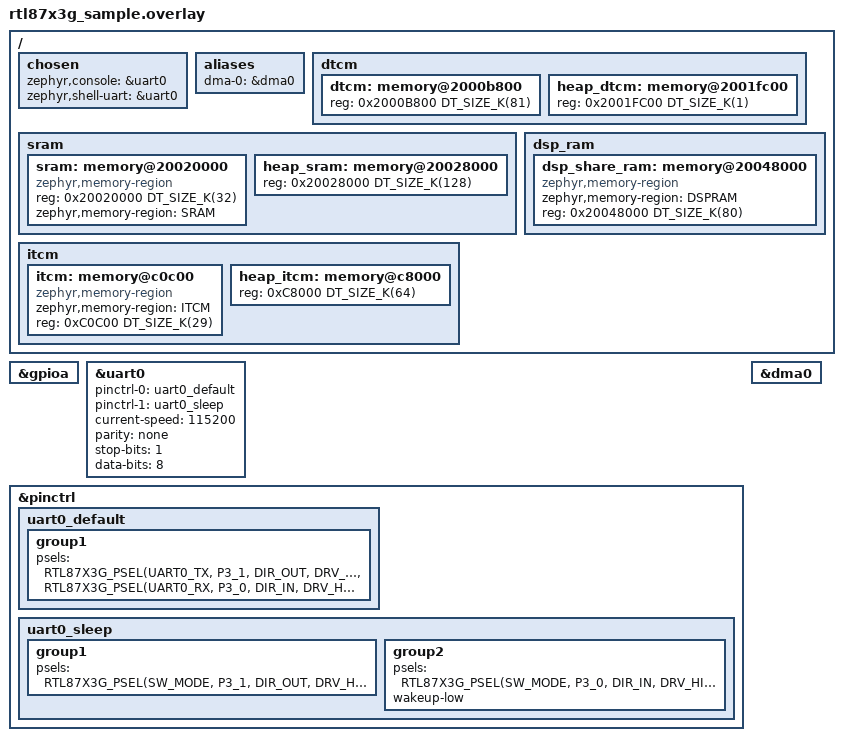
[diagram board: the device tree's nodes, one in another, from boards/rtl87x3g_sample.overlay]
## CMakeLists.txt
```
#
# Copyright (c) 2026, Realtek Semiconductor Corporation
#
# SPDX-License-Identifier: LicenseRef-Realtek-5-Clause
#

message(STATUS "CMAKELIST FOLDER: ${CMAKE_CURRENT_SOURCE_DIR}")

cmake_minimum_required(VERSION 3.20.0)

#===========version generation===========
include(${CMAKE_CURRENT_SOURCE_DIR}/../../cmake/version_generate.cmake)
generate_version()
#===========version generation===========
#===========post build===========
# post build should be called before find_package
include(${CMAKE_CURRENT_SOURCE_DIR}/../../cmake/post_build.cmake)
rtk_post_build()
#===========post build===========

find_package(Zephyr REQUIRED HINTS $ENV{ZEPHYR_BASE})
project(ble_scatternet)

FILE(GLOB app_sources src/*.c)
target_sources(app PRIVATE
  ${app_sources}
  )

set(sources
   ${ZEPHYR_REALTEK_APP_MODULE_DIR}/subsys/bluetooth/gatt_profile/src/client/ancs_client.c
   ${ZEPHYR_REALTEK_APP_MODULE_DIR}/subsys/bluetooth/gatt_profile/src/client/bas_client.c
   ${ZEPHYR_REALTEK_APP_MODULE_DIR}/subsys/bluetooth/gatt_profile/src/client/simple_ble_client.c
   ${ZEPHYR_REALTEK_APP_MODULE_DIR}/subsys/bluetooth/gatt_profile/src/client/gaps_client.c
   ${ZEPHYR_REALTEK_APP_MODULE_DIR}/subsys/bluetooth/gatt_profile/src/server/bas.c
   ${ZEPHYR_REALTEK_APP_MODULE_DIR}/subsys/bluetooth/gatt_profile/src/server/dis.c
   ${ZEPHYR_REALTEK_APP_MODULE_DIR}/subsys/bluetooth/gatt_profile/src/server/simple_ble_service.c
   )

set(headers
    #header files from app
	src/
    #header files from libs
    ${ZEPHYR_REALTEK_APP_MODULE_DIR}/subsys/bluetooth/gatt_profile/inc/bt_gatt_client
    ${ZEPHYR_REALTEK_APP_MODULE_DIR}/subsys/bluetooth/gatt_profile/inc/bt_gatt_svc
    ${ZEPHYR_REALTEK_APP_MODULE_DIR}/subsys/bluetooth/gatt_profile/inc/client
    ${ZEPHYR_REALTEK_APP_MODULE_DIR}/subsys/bluetooth/gatt_profile/inc/server
    )

foreach(header ${headers})
    if(EXISTS ${header})
        zephyr_include_directories(${header})
    else()
        message(FATAL_ERROR "header file directory does not exist: ${header}. Current cmakelist: ${CMAKE_CURRENT_SOURCE_DIR}")
    endif()
endforeach()

foreach(src ${sources})
    if(EXISTS ${src})
        target_sources(app PRIVATE ${src})
    else()
        message(FATAL_ERROR "source file does not exist: ${src}. Current cmakelist: ${CMAKE_CURRENT_SOURCE_DIR}")
    endif()
endforeach()

target_precompile_headers(app PUBLIC
	          ${CMAKE_CURRENT_SOURCE_DIR}/src/app_scatternet_flags.h
			  )

target_include_directories(app PRIVATE src)
```

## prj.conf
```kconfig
# nothing here
CONFIG_REALTEK_SUBSYS_BLE_MGR=y

# Network shell
CONFIG_SERIAL=y
CONFIG_UART_CONSOLE=y
CONFIG_UART_INTERRUPT_DRIVEN=y
CONFIG_UART_ASYNC_API=y
CONFIG_SHELL=y
CONFIG_SHELL_BACKEND_SERIAL=y
CONFIG_LOG_RTK=n
CONFIG_PRINTK=y
CONFIG_HEAP_MEM_POOL_SIZE=1024
CONFIG_CONSOLE=y
#CONFIG_STDOUT_CONSOLE=y

#CONFIG_UART_SHELL_ON_DEV_NAME="UART_2"
#CONFIG_SHELL_PROMPT_UART="uart:~$ "
```

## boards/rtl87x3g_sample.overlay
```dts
/*
 * Copyright(c) 2024, Realtek Semiconductor Corporation.
 *
 * SPDX-License-Identifier: Apache-2.0
 */

#include <zephyr/dt-bindings/gpio/realtek-rtl87x3g-gpio.h>
#include <dt-bindings/pinctrl/rtl87x3g-pinctrl.h>
#include <dt-bindings/input/input-event-codes.h>

&gpioa {
	status = "okay";
};

/ {
    chosen {
        zephyr,console = &uart0;
        zephyr,shell-uart = &uart0;
    };
};

/**
#define GDMA_Handshake_UART0_TX                                     (0)
#define GDMA_Handshake_UART0_RX                                     (1)
#define GDMA_Handshake_UART2_TX                                     (2)
#define GDMA_Handshake_UART2_RX                                     (3)
#define GDMA_Handshake_UART3_TX                                     (48)
#define GDMA_Handshake_UART3_RX                                     (49)
#define GDMA_Handshake_UART4_TX                                     (50)
#define GDMA_Handshake_UART4_RX                                     (51)
#define GDMA_Handshake_UART5_TX                                     (52)
#define GDMA_Handshake_UART5_RX                                     (53)
*/

&uart0 {
	pinctrl-0 = <&uart0_default>;
	pinctrl-1 = <&uart0_sleep>;
	pinctrl-names = "default", "sleep";
	status = "okay";
	current-speed = <115200>;
	parity = "none";
	stop-bits = "1";
	data-bits = <8>;
	//dmas = <&dma0 2 3 0xa>, <&dma0 3 2 0x10021>;
	//dma-names = "rx", "tx";
};

&pinctrl
{
	uart0_default:uart0_default {
		group1 {
			psels = <RTL87X3G_PSEL(UART0_TX, P3_1, DIR_OUT, DRV_HIGH, PULL_UP)>,
			<RTL87X3G_PSEL(UART0_RX, P3_0, DIR_IN, DRV_HIGH, PULL_UP)>;
		};
	};

	uart0_sleep:uart0_sleep {
		group1 {
			psels = <RTL87X3G_PSEL(SW_MODE, P3_1, DIR_OUT, DRV_HIGH, PULL_UP)>;
		};
		group2 {
			psels = <RTL87X3G_PSEL(SW_MODE, P3_0, DIR_IN, DRV_HIGH, PULL_UP)>;
			wakeup-low;
		};
	};
};

&dma0 {
	status = "okay";
};

&gpioa {
	status = "okay";
};

/*delete-node only support nodes with lable */
/delete-node/ &dtcm;
/delete-node/ &heap_dtcm;
/delete-node/ &sram;
/delete-node/ &heap_sram;
/delete-node/ &itcm;
/delete-node/ &heap_itcm;
/delete-node/ &dsp_share_ram;

/ {
	aliases {
		dma-0 = &dma0;
    };

	/* DTCM addr: 0x20000000~0x20020000, total size: 128KByte.
	 * The front 46Kbyte was taken by RTK internal.
	 * If users wants to increase global variables and zephyr static heap,
	 * please follow the steps:
	 * 1. increase dtcm size value "reg = <0x2000B800 DT_SIZE_K(NEW_SIZE)>"
	 * 2. modify heap_dtcm addr label "heap_dtcm: memory@NEW_ADDR"
	 * 3. modify heap_dtcm reg addr "reg = <NEW_ADDR DT_SIZE_K(NEW_SIZE)>"
	 * 4. decrease heap_dtcm size value "reg = <NEW_ADDR DT_SIZE_K(NEW_SIZE)>"
	 * Warning:
	 * 1. the dtcm address should NOT modified!
	 * 2. the dtcm plus heap_dtcm size should NOT exceed 82KByte!
	 */
	dtcm {
		dtcm: memory@2000b800 {
			device_type = "dtcm region";
			reg = <0x2000B800 DT_SIZE_K(81)>;
		};
		heap_dtcm: memory@2001fc00 {
			device_type = "heap dtcm region";
			reg = <0x2001FC00 DT_SIZE_K(1)>;
		};
	};
	/* sram addr: 0x20020000~0x20048000, total size: 160KByte.
	 * call zephyr_code_relocate(FILES xxx.x LOCATION SRAM) at cmakelist could relocate variables on sram.
	 * for more information, please refer to https://docs.zephyrproject.org/latest/kernel/code-relocation.html
	 * If users wants to increase sram size, please follow the steps:
	 * 1. increase sram size value "reg = <0x20020000 DT_SIZE_K(NEW_SIZE)>"
	 * 2. modify heap_sram addr label "heap_sram: memory@NEW_ADDR"
	 * 3. modify heap_sram reg addr "reg = <NEW_ADDR DT_SIZE_K(NEW_SIZE)>"
	 * 4. decrease heap_sram size value "reg = <NEW_ADDR DT_SIZE_K(NEW_SIZE)>"
	 * Warning:
	 * 1. the sram address should NOT modified!
	 * 2. the sram plus heap_sram size should NOT exceed 160KByte!
	 */
	sram {
		sram: memory@20020000 {
			device_type = "sram region";
			compatible = "zephyr,memory-region", "mmio-sram";
			reg = <0x20020000 DT_SIZE_K(32)>;
			zephyr,memory-region = "SRAM";
		};
		heap_sram: memory@20028000 {
			device_type = "heap sram region";
			reg = <0x20028000 DT_SIZE_K(128)>;
		};
	};

	itcm {
		itcm: memory@c0c00 {
			device_type = "itcm region";
			compatible = "zephyr,memory-region", "arm,itcm";
			zephyr,memory-region = "ITCM";
			reg = <0xC0C00 DT_SIZE_K(29)>;
		};
		heap_itcm: memory@c8000 {
			device_type = "heap itcm region";
			reg = <0xC8000 DT_SIZE_K(64)>;
		};
	};

	dsp_ram {
		dsp_share_ram: memory@20048000 {
			compatible = "zephyr,memory-region";
			device_type = "dsp_share_ram region";
			zephyr,memory-region = "DSPRAM";
			reg = <0x20048000 DT_SIZE_K(80)>;
		};
	};
};
```

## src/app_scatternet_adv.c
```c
/*
 * Copyright (c) 2026, Realtek Semiconductor Corporation
 *
 * SPDX-License-Identifier: LicenseRef-Realtek-5-Clause
 */

/*============================================================================*
 *                              Header Files
 *============================================================================*/
#include "ftl.h"
#include "trace.h"
#include "stdint.h"
#include "string.h"
#include "app_shell_cmd.h"
#include "ble_ext_adv.h"
#include "app_scatternet_adv.h"
#include "simple_ble_service.h"

/** @defgroup SCATTERNET_APP Scatternet Application
  * @brief Scatternet Application
  * @{
  */
/*============================================================================*
 *                              Constants
 *============================================================================*/

#define HI_WORD(x)  ((uint8_t)((x & 0xFF00) >> 8))
#define LO_WORD(x)  ((uint8_t)(x))

#define APP_STATIC_RANDOM_ADDR_OFFSET 0xC00

/*============================================================================*
 *                              Variables
 *============================================================================*/
uint8_t adv_handle = 0xFF;
static T_BLE_EXT_ADV_MGR_STATE adv_state = BLE_EXT_ADV_MGR_ADV_DISABLED;

/**
 * @brief scan response data struct
 *
 */
uint8_t scan_rsp_data[] =
{
    0x03,/* length */
    GAP_ADTYPE_APPEARANCE,/* type="Appearance" */
    LO_WORD(GAP_GATT_APPEARANCE_UNKNOWN),
    HI_WORD(GAP_GATT_APPEARANCE_UNKNOWN),
};

/**
 * @brief advertising data struct
 *
 */
uint8_t adv_data[] =
{
    /* Flags */
    0x02,/* length */
    GAP_ADTYPE_FLAGS,/* type="Flags" */
    GAP_ADTYPE_FLAGS_LIMITED | GAP_ADTYPE_FLAGS_BREDR_NOT_SUPPORTED,

    /* Service */
    0x03,/* length */
    GAP_ADTYPE_16BIT_COMPLETE,/*type="16 bit uuid"*/
    LO_WORD(GATT_UUID_SIMPLE_PROFILE),
    HI_WORD(GATT_UUID_SIMPLE_PROFILE),

    /* Local name */
    0x0F,/* length */
    GAP_ADTYPE_LOCAL_NAME_COMPLETE,/*type="name"*/
    'B', 'L', 'E', '_', 'S', 'C', 'A', 'T', 'T', 'E', 'R', 'N', 'E', 'T',
};

/**
 * @brief static random address struct which is storged in ftl
 *
 */
typedef struct
{
    uint8_t is_exist;
    uint8_t reserved;
    uint8_t bd_addr[GAP_BD_ADDR_LEN];
} T_APP_STATIC_RANDOM_ADDR;

/*============================================================================*
 *                              Functions
 *============================================================================*/

/**
 * @brief app_adv_callback
 *
 * @param cb_type
 * @ref BLE_EXT_ADV_STATE_CHANGE this message will be send to APP when advertising state changed
 * @ref BLE_EXT_ADV_SET_CONN_INFO this message will be send to APP when connection state changed
 *
 * @param p_cb_data
 */
void app_adv_callback(uint8_t cb_type, void *p_cb_data)
{
    T_BLE_EXT_ADV_CB_DATA cb_data;
    memcpy(&cb_data, p_cb_data, sizeof(T_BLE_EXT_ADV_CB_DATA));

    switch (cb_type)
    {
    case BLE_EXT_ADV_STATE_CHANGE:
        {
            APP_PRINT_TRACE2("app_adv_callback: adv_state %d, adv_handle %d",
                             cb_data.p_ble_state_change->state, cb_data.p_ble_state_change->adv_handle);
            adv_state = cb_data.p_ble_state_change->state;

            if (adv_state == BLE_EXT_ADV_MGR_ADV_ENABLED)
            {
                APP_PRINT_TRACE0("app_adv_callback: BLE_EXT_ADV_MGR_ADV_ENABLED");
                app_shell_print("GAP adv start\r\n");
            }
            else if (adv_state == BLE_EXT_ADV_MGR_ADV_DISABLED)
            {
                APP_PRINT_TRACE0("app_adv_callback: BLE_EXT_ADV_MGR_ADV_DISABLED");
                app_shell_print("GAP adv stoped\r\n");
                switch (cb_data.p_ble_state_change->stop_cause)
                {
                case BLE_EXT_ADV_STOP_CAUSE_APP:
                    break;

                case BLE_EXT_ADV_STOP_CAUSE_CONN:
                    break;

                case BLE_EXT_ADV_STOP_CAUSE_TIMEOUT:
                    break;

                default:
                    break;
                }
                APP_PRINT_TRACE2("app_adv_callback: stack stop adv cause 0x%x, app stop adv cause 0x%02x",
                                 cb_data.p_ble_state_change->stop_cause, cb_data.p_ble_state_change->app_cause);
            }
        }
        break;

    case BLE_EXT_ADV_SET_CONN_INFO:
        APP_PRINT_TRACE2("app_adv_callback: BLE_EXT_ADV_SET_CONN_INFO conn_id 0x%x, adv_handle %d",
                         cb_data.p_ble_conn_info->conn_id, cb_data.p_ble_conn_info->adv_handle);
        break;

    default:
        break;
    }
}

/**
 * @brief app_adv_load_static_random_address
 * if random address already exist in ftl, then load this address.
 * @param p_addr
 * @return uint32_t
 */
uint32_t app_adv_load_static_random_address(T_APP_STATIC_RANDOM_ADDR *p_addr)
{
    uint32_t result;
    result = ftl_load_from_storage(p_addr, APP_STATIC_RANDOM_ADDR_OFFSET,
                                   sizeof(T_APP_STATIC_RANDOM_ADDR));
    APP_PRINT_INFO1("app_adv_load_static_random_address: result 0x%x", result);
    if (result)
    {
        memset(p_addr, 0, sizeof(T_APP_STATIC_RANDOM_ADDR));
    }
    return result;
}

/**
 * @brief app_adv_save_static_random_address
 * save static random address into ftl
 * @param p_addr
 * @return uint32_t
 */
uint32_t app_adv_save_static_random_address(T_APP_STATIC_RANDOM_ADDR *p_addr)
{
    APP_PRINT_INFO0("app_adv_save_static_random_address");
    return ftl_save_to_storage(p_addr, APP_STATIC_RANDOM_ADDR_OFFSET, sizeof(T_APP_STATIC_RANDOM_ADDR));
}

/**
 * @brief app_adv_init_conn_public
 *        advertising parameter initialization: use public address to advertise connectable advertising.
 * adv_handle        Identify an advertising set, which is assigned by @ref ble_ext_adv_mgr_init_adv_params.
 * adv_event_prop    Type of advertising event.
 *                   Values for legacy advertising PDUs: @ref T_LE_EXT_ADV_LEGACY_ADV_PROPERTY.
 * adv_interval_min  Minimum advertising interval for undirected and low duty directed advertising.
 *                   In units of 0.625ms, range: 0x000020 to 0xFFFFFF.
 * adv_interval_max  Maximum advertising interval for undirected and low duty directed advertising.
 *                   In units of 0.625ms, range: 0x000020 to 0xFFFFFF.
 * own_address_type  Local address type, @ref T_GAP_LOCAL_ADDR_TYPE.
 * peer_address_type Remote address type, GAP_REMOTE_ADDR_LE_PUBLIC or GAP_REMOTE_ADDR_LE_RANDOM in @ref T_GAP_REMOTE_ADDR_TYPE.
 *                   GAP_REMOTE_ADDR_LE_PUBLIC: Public Device Address or Public Identity Address.
 *                   GAP_REMOTE_ADDR_LE_RANDOM: Random Device Address or Random(static) Identity Address.
 * peer_address      Remote address.
 * filter_policy     Advertising filter policy: @ref T_GAP_ADV_FILTER_POLICY.
 */
void app_adv_init_conn_public(void)
{
    T_LE_EXT_ADV_LEGACY_ADV_PROPERTY adv_event_prop = LE_EXT_ADV_LEGACY_ADV_CONN_SCAN_UNDIRECTED;
    uint16_t adv_interval_min = 0xA0;
    uint16_t adv_interval_max = 0xB0;
    T_GAP_LOCAL_ADDR_TYPE own_address_type = GAP_LOCAL_ADDR_LE_PUBLIC;
    T_GAP_REMOTE_ADDR_TYPE peer_address_type = GAP_REMOTE_ADDR_LE_PUBLIC;
    uint8_t  peer_address[6] = {0, 0, 0, 0, 0, 0};
    T_GAP_ADV_FILTER_POLICY filter_policy = GAP_ADV_FILTER_ANY;

    ble_ext_adv_mgr_init_adv_params(&adv_handle, adv_event_prop, adv_interval_min,
                                    adv_interval_max, own_address_type, peer_address_type, peer_address,
                                    filter_policy, sizeof(adv_data), adv_data,
                                    sizeof(scan_rsp_data), scan_rsp_data, NULL);

    ble_ext_adv_mgr_register_callback(app_adv_callback, adv_handle);
}

/**
 * @brief app_adv_init_conn_random
 *        advertising parameter initialization: use static random address to advertise connectable advertising.
 * adv_handle        Identify an advertising set, which is assigned by @ref ble_ext_adv_mgr_init_adv_params.
 * adv_event_prop    Type of advertising event.
 *                   Values for legacy advertising PDUs: @ref T_LE_EXT_ADV_LEGACY_ADV_PROPERTY.
 * adv_interval_min  Minimum advertising interval for undirected and low duty directed advertising.
 *                   In units of 0.625ms, range: 0x000020 to 0xFFFFFF.
 * adv_interval_max  Maximum advertising interval for undirected and low duty directed advertising.
 *                   In units of 0.625ms, range: 0x000020 to 0xFFFFFF.
 * own_address_type  Local address type, @ref T_GAP_LOCAL_ADDR_TYPE.
 * peer_address_type Remote address type, GAP_REMOTE_ADDR_LE_PUBLIC or GAP_REMOTE_ADDR_LE_RANDOM in @ref T_GAP_REMOTE_ADDR_TYPE.
 *                   GAP_REMOTE_ADDR_LE_PUBLIC: Public Device Address or Public Identity Address.
 *                   GAP_REMOTE_ADDR_LE_RANDOM: Random Device Address or Random(static) Identity Address.
 * peer_address      Remote address.
 * filter_policy     Advertising filter policy: @ref T_GAP_ADV_FILTER_POLICY.
 */
void app_adv_init_conn_random(void)
{
    T_LE_EXT_ADV_LEGACY_ADV_PROPERTY adv_event_prop = LE_EXT_ADV_LEGACY_ADV_CONN_SCAN_UNDIRECTED;
    uint16_t adv_interval_min = 0xA0;
    uint16_t adv_interval_max = 0xB0;
    T_GAP_LOCAL_ADDR_TYPE own_address_type = GAP_LOCAL_ADDR_LE_RANDOM;
    T_GAP_REMOTE_ADDR_TYPE peer_address_type = GAP_REMOTE_ADDR_LE_PUBLIC;
    uint8_t  peer_address[6] = {0, 0, 0, 0, 0, 0};
    T_GAP_ADV_FILTER_POLICY filter_policy = GAP_ADV_FILTER_ANY;

    bool gen_addr = true;
    T_APP_STATIC_RANDOM_ADDR random_addr;

    if (app_adv_load_static_random_address(&random_addr) == 0)
    {
        if ((random_addr.is_exist == true) && ((random_addr.bd_addr[5] & 0xC0) == 0xC0))
        {
            gen_addr = false;
        }
    }
    if (gen_addr)
    {
        if (le_gen_rand_addr(GAP_RAND_ADDR_STATIC, random_addr.bd_addr) == GAP_CAUSE_SUCCESS)
        {
            random_addr.is_exist = true;
            app_adv_save_static_random_address(&random_addr);
        }
    }
    APP_PRINT_INFO1("app_peripheral_adv_init_conn_random: random address %b",
                    TRACE_BDADDR(random_addr.bd_addr));

    ble_ext_adv_mgr_init_adv_params(&adv_handle, adv_event_prop, adv_interval_min,
                                    adv_interval_max, own_address_type, peer_address_type, peer_address,
                                    filter_policy, sizeof(adv_data), adv_data,
                                    sizeof(scan_rsp_data), scan_rsp_data, random_addr.bd_addr);

    ble_ext_adv_mgr_register_callback(app_adv_callback, adv_handle);
}

/**
 * @brief app_adv_start
 *        start advertising
 * @param duration_10ms If non-zero, indicates the duration that advertising is enabled.
                        0x0000:        Always advertising, no advertising duration.
                        0x0001-0xFFFF: Advertising duration, in units of 10ms.
 * @return true         BLE protocol stack has already receive this command and ready to execute,
 *                      when this command execution complete, BLE protocol stack will send BLE_EXT_ADV_MGR_ADV_ENABLED to APP. @ref app_peripheral_adv_callback
 * @return false        There has some errors that cause the BLE protocol stack fail to receive this command.
 */
bool app_adv_start(uint16_t duration_10ms)
{
    if (adv_state == BLE_EXT_ADV_MGR_ADV_DISABLED)
    {
        APP_PRINT_INFO0("app_adv_start");
        if (ble_ext_adv_mgr_enable(adv_handle, duration_10ms) == GAP_CAUSE_SUCCESS)
        {
            return true;
        }
        return false;
    }

    APP_PRINT_TRACE0("app_adv_start: Already started");
    return true;
}

/**
 * @brief app_adv_stop
 *        stop advertising
 * @param app_cause please reference app_adv_stop_cause.h
 *                  if you want to add new advertising stop cause, please added in app_adv_stop_cause.h
 * @return true     BLE protocol stack has already receive this command and ready to execute,
 *                  when this command execution complete, BLE protocol stack will send BLE_EXT_ADV_MGR_ADV_DISABLED to APP. @ref app_peripheral_adv_callback
 * @return false    There has some errors that cause the BLE protocol stack fail to receive this command.
 */
bool app_adv_stop(int8_t app_cause)
{
    if (adv_state == BLE_EXT_ADV_MGR_ADV_ENABLED)
    {
        if (ble_ext_adv_mgr_disable(adv_handle, app_cause) == GAP_CAUSE_SUCCESS)
        {
            APP_PRINT_INFO0("app_adv_stop");
            return true;
        }
        return false;
    }

    APP_PRINT_TRACE0("app_adv_stop: Already stoped");
    return true;
}

/**
 * @brief app_adv_get_state
 *        get advertising state
 * @return T_BLE_EXT_ADV_MGR_STATE
 */
T_BLE_EXT_ADV_MGR_STATE app_adv_get_state(void)
{
    return ble_ext_adv_mgr_get_adv_state(adv_handle);
}

/**
 * @brief app_adv_update_randomaddr  update random address
 *
 * @param random_address
 * @return T_GAP_CAUSE
 */
T_GAP_CAUSE app_adv_update_randomaddr(uint8_t *random_address)
{
    return ble_ext_adv_mgr_set_random(adv_handle, random_address);
}

/**
 * @brief app_adv_update_advdata  update advertising data
 *
 * @param p_adv_data   BLE protocol stack will not reallocate memory for adv data,
 *                     so p_adv_data shall point to a global memory.
 *                     if you don't want to set adv data, set default value NULL.
 * @param adv_data_len Advertising data or scan response data length shall not exceed 31 bytes.
 * @return T_GAP_CAUSE
 */
T_GAP_CAUSE app_adv_update_advdata(uint8_t *p_adv_data, uint16_t adv_data_len)
{
    return ble_ext_adv_mgr_set_adv_data(adv_handle, adv_data_len, p_adv_data);
}

/**
 * @brief app_adv_update_scanrspdata update scan response data
 *
 * @param p_scan_data   BLE protocol stack will not reallocate memory for scan response data,
 *                      so p_scan_data shall point to a global memory.
 *                      if you don't want to set scan response data, set default value NULL.
 * @param scan_data_len Advertising data or scan response data length shall not exceed 31 bytes.
 * @return T_GAP_CAUSE
 */
T_GAP_CAUSE app_adv_update_scanrspdata(uint8_t *p_scan_data, uint16_t scan_data_len)
{
    return ble_ext_adv_mgr_set_scan_response_data(adv_handle, scan_data_len, p_scan_data);
}

/**
 * @brief app_adv_update_interval update advertising interval
 *
 * @param adv_interval advertising interval for undirected and low duty directed advertising.
 *                     In units of 0.625ms, range: 0x000020 to 0xFFFFFF.
 * @return T_GAP_CAUSE
 */
T_GAP_CAUSE app_adv_update_interval(uint16_t adv_interval)
{
    return ble_ext_adv_mgr_change_adv_interval(adv_handle, adv_interval);
}

/** End of SCATTERNET_APP
* @}
*/
```

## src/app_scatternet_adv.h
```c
/*
 * Copyright (c) 2026, Realtek Semiconductor Corporation
 *
 * SPDX-License-Identifier: LicenseRef-Realtek-5-Clause
 */

#ifndef _APP_SCATTERNET_ADV__
#define _APP_SCATTERNET_ADV__

#ifdef __cplusplus
extern "C" {
#endif

/*============================================================================*
 *                              Header Files
 *============================================================================*/
#include "stdbool.h"
#include "stdint.h"
#include "ble_ext_adv.h"

/** @defgroup SCATTERNET_APP Scatternet Application
  * @brief Scatternet Application
  * @{
  */

/*============================================================================*
 *                              Functions
 *============================================================================*/
/**
 * @brief app_adv_init_conn_public
 *        advertising parameter initialization: use public address to advertise connectable undirected advertising.
 *        Advertising data or scan response data shall not exceed 31 bytes.
 * adv_handle        Identify an advertising set, which is assigned by @ref ble_ext_adv_mgr_init_adv_params.
 * adv_event_prop    Type of advertising event.
 *                   Values for legacy advertising PDUs: @ref T_LE_EXT_ADV_LEGACY_ADV_PROPERTY.
 * adv_interval_min  Minimum advertising interval for undirected and low duty directed advertising.
 *                   In units of 0.625ms, range: 0x000020 to 0xFFFFFF.
 * adv_interval_max  Maximum advertising interval for undirected and low duty directed advertising.
 *                   In units of 0.625ms, range: 0x000020 to 0xFFFFFF.
 * own_address_type  Local address type, @ref T_GAP_LOCAL_ADDR_TYPE.
 * peer_address_type Remote address type, GAP_REMOTE_ADDR_LE_PUBLIC or GAP_REMOTE_ADDR_LE_RANDOM in @ref T_GAP_REMOTE_ADDR_TYPE.
 *                   GAP_REMOTE_ADDR_LE_PUBLIC: Public Device Address or Public Identity Address.
 *                   GAP_REMOTE_ADDR_LE_RANDOM: Random Device Address or Random(static) Identity Address.
 * peer_address      Remote address.
 * filter_policy     Advertising filter policy: @ref T_GAP_ADV_FILTER_POLICY.
 */
void app_adv_init_conn_public(void);

/**
 * @brief app_adv_init_conn_random
 *        advertising parameter initialization: use static random address to advertise connectable undirected advertising.
 *        Advertising data or scan response data shall not exceed 31 bytes.
 * adv_handle        Identify an advertising set, which is assigned by @ref ble_ext_adv_mgr_init_adv_params.
 * adv_event_prop    Type of advertising event.
 *                   Values for legacy advertising PDUs: @ref T_LE_EXT_ADV_LEGACY_ADV_PROPERTY.
 * adv_interval_min  Minimum advertising interval for undirected and low duty directed advertising.
 *                   In units of 0.625ms, range: 0x000020 to 0xFFFFFF.
 * adv_interval_max  Maximum advertising interval for undirected and low duty directed advertising.
 *                   In units of 0.625ms, range: 0x000020 to 0xFFFFFF.
 * own_address_type  Local address type, @ref T_GAP_LOCAL_ADDR_TYPE.
 * peer_address_type Remote address type, GAP_REMOTE_ADDR_LE_PUBLIC or GAP_REMOTE_ADDR_LE_RANDOM in @ref T_GAP_REMOTE_ADDR_TYPE.
 *                   GAP_REMOTE_ADDR_LE_PUBLIC: Public Device Address or Public Identity Address.
 *                   GAP_REMOTE_ADDR_LE_RANDOM: Random Device Address or Random(static) Identity Address.
 * peer_address      Remote address.
 * filter_policy     Advertising filter policy: @ref T_GAP_ADV_FILTER_POLICY.
 */
void app_adv_init_conn_random(void);

/**
 * @brief app_adv_start
 *        start advertising
 * @param duration_10ms If non-zero, indicates the duration that advertising is enabled.
                        0x0000:        Always advertising, no advertising duration.
                        0x0001-0xFFFF: Advertising duration, in units of 10ms.
 * @return true         BLE protocol stack has already receive this command and ready to execute,
 *                      when this command execution complete, BLE protocol stack will send BLE_EXT_ADV_MGR_ADV_ENABLED to APP. @ref app_peripheral_adv_callback
 * @return false        There has some errors that cause the BLE protocol stack fail to receive this command.
 */
bool app_adv_start(uint16_t duration_10ms);

/**
 * @brief app_adv_stop
 *        stop advertising
 * @param app_cause please reference app_adv_stop_cause.h
 *                  if you want to add new advertising stop cause, please added in app_adv_stop_cause.h
 * @return true     BLE protocol stack has already receive this command and ready to execute,
 *                  when this command execution complete, BLE protocol stack will send BLE_EXT_ADV_MGR_ADV_DISABLED to APP. @ref app_peripheral_adv_callback
 * @return false    There has some errors that cause the BLE protocol stack fail to receive this command.
 */
bool app_adv_stop(int8_t app_cause);

/**
 * @brief app_adv_get_state
 *        get advertising state
 * @return T_BLE_EXT_ADV_MGR_STATE
 */
T_BLE_EXT_ADV_MGR_STATE app_adv_get_state(void);

/**
 * @brief app_adv_update_randomaddr  update random address
 *
 * @param random_address
 * @return T_GAP_CAUSE
 */
T_GAP_CAUSE app_adv_update_randomaddr(uint8_t *random_address);

/**
 * @brief app_adv_update_advdata  update advertising data
 *
 * @param p_adv_data   BLE protocol stack will not reallocate memory for adv data,
 *                     so p_adv_data shall point to a global memory.
 *                     if you don't want to set adv data, set default value NULL.
 * @param adv_data_len Advertising data or scan response data length shall not exceed 31 bytes.
 * @return T_GAP_CAUSE
 */
T_GAP_CAUSE app_adv_update_advdata(uint8_t *p_adv_data, uint16_t adv_data_len);

/**
 * @brief app_adv_update_scanrspdata update scan response data
 *
 * @param p_scan_data   BLE protocol stack will not reallocate memory for scan response data,
 *                      so p_scan_data shall point to a global memory.
 *                      if you don't want to set scan response data, set default value NULL.
 * @param scan_data_len Advertising data or scan response data length shall not exceed 31 bytes.
 * @return T_GAP_CAUSE
 */
T_GAP_CAUSE app_adv_update_scanrspdata(uint8_t *p_scan_data, uint16_t scan_data_len);

/**
 * @brief app_adv_update_interval update advertising interval
 *
 * @param adv_interval advertising interval for undirected and low duty directed advertising.
 *                     In units of 0.625ms, range: 0x000020 to 0xFFFFFF.
 * @return T_GAP_CAUSE
 */
T_GAP_CAUSE app_adv_update_interval(uint16_t adv_interval);

/**
 * @brief app_adv_callback
 *
 * @param cb_type
 * @ref BLE_EXT_ADV_STATE_CHANGE this message will be send to APP when advertising state changed
 * @ref BLE_EXT_ADV_SET_CONN_INFO this message will be send to APP when connection state changed
 *
 * @param p_cb_data
 */
void app_adv_callback(uint8_t cb_type, void *p_cb_data);
/** End of SCATTERNET_APP
* @}
*/

#ifdef __cplusplus
}
#endif
#endif
```

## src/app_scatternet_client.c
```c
/*
 * Copyright (c) 2026, Realtek Semiconductor Corporation
 *
 * SPDX-License-Identifier: LicenseRef-Realtek-5-Clause
 */

/*============================================================================*
 *                              Header Files
 *============================================================================*/
#include "trace.h"
#include "gaps_client.h"
#include "bas_client.h"
#include "simple_ble_client.h"
#include "app_scatternet_client.h"
#include "app_scatternet_link_mgr.h"

/** @defgroup SCATTERNET_APP Scatternet Application
    * @brief This file handles BLE Scatternet application routines.
    * @{
    */
T_CLIENT_ID simple_ble_client_id;/**< Simple ble service client id*/
T_CLIENT_ID gaps_client_id;/**< gap service client id*/
T_CLIENT_ID bas_client_id;/**< battery service client id*/

/*============================================================================*
 *                              Functions
 *============================================================================*/
/** @defgroup  CENTRAL_CLIIENT_CALLBACK Profile Client Callback Event Handler
    * @brief Handle profile client callback event
    * @{
    */
/**
 * @brief app_client_callback
          Callback will be called when data sent from profile client layer.
 * @param  client_id the ID distinguish which module sent the data.
 * @param  conn_id   connection ID.
 * @param  p_data    pointer to data.
 * @retval result    @ref T_APP_RESULT
 */
T_APP_RESULT app_client_callback(T_CLIENT_ID client_id, uint8_t conn_id, void *p_data)
{
    T_APP_RESULT  result = APP_RESULT_SUCCESS;
    APP_PRINT_INFO2("app_client_callback: client_id %d, conn_id %d", client_id, conn_id);

    if (client_id == gaps_client_id)
    {
        T_GAPS_CLIENT_CB_DATA *p_gaps_cb_data = (T_GAPS_CLIENT_CB_DATA *)p_data;
        switch (p_gaps_cb_data->cb_type)
        {
        case GAPS_CLIENT_CB_TYPE_DISC_STATE:
            switch (p_gaps_cb_data->cb_content.disc_state)
            {
            case DISC_GAPS_DONE:
                APP_PRINT_INFO0("app_client_callback: discover gaps procedure done.");
                break;

            case DISC_GAPS_FAILED:
                APP_PRINT_INFO0("app_client_callback: discover gaps request failed.");
                break;

            default:
                break;
            }
            break;

        case GAPS_CLIENT_CB_TYPE_READ_RESULT:
            switch (p_gaps_cb_data->cb_content.read_result.type)
            {
            case GAPS_READ_DEVICE_NAME:
                if (p_gaps_cb_data->cb_content.read_result.cause == GAP_SUCCESS)
                {
                    APP_PRINT_INFO1("app_client_callback: GAPS_READ_DEVICE_NAME device name %s.",
                                    TRACE_STRING(p_gaps_cb_data->cb_content.read_result.data.device_name.p_value));
                }
                else
                {
                    APP_PRINT_INFO1("app_client_callback: GAPS_READ_DEVICE_NAME failded cause 0x%x",
                                    p_gaps_cb_data->cb_content.read_result.cause);
                }
                break;

            case GAPS_READ_APPEARANCE:
                if (p_gaps_cb_data->cb_content.read_result.cause == GAP_SUCCESS)
                {
                    APP_PRINT_INFO1("app_client_callback: GAPS_READ_APPEARANCE appearance %d",
                                    p_gaps_cb_data->cb_content.read_result.data.appearance);
                }
                else
                {
                    APP_PRINT_INFO1("app_client_callback: GAPS_READ_APPEARANCE failded cause 0x%x",
                                    p_gaps_cb_data->cb_content.read_result.cause);
                }
                break;

            case GAPS_READ_CENTRAL_ADDR_RESOLUTION:
                if (p_gaps_cb_data->cb_content.read_result.cause == GAP_SUCCESS)
                {
                    APP_PRINT_INFO1("app_client_callback: GAPS_READ_CENTRAL_ADDR_RESOLUTION central_addr_res %d",
                                    p_gaps_cb_data->cb_content.read_result.data.central_addr_res);
                }
                else
                {
                    APP_PRINT_INFO1("app_client_callback: GAPS_READ_CENTRAL_ADDR_RESOLUTION failded cause 0x%x",
                                    p_gaps_cb_data->cb_content.read_result.cause);
                }
                break;

            default:
                break;
            }
            break;

        default:
            break;
        }
    }
    else if (client_id == simple_ble_client_id)
    {
        T_SIMP_CLIENT_CB_DATA *p_simp_client_cb_data = (T_SIMP_CLIENT_CB_DATA *)p_data;
        uint16_t value_size;
        uint8_t *p_value;
        switch (p_simp_client_cb_data->cb_type)
        {
        case SIMP_CLIENT_CB_TYPE_DISC_STATE:
            switch (p_simp_client_cb_data->cb_content.disc_state)
            {
            case DISC_SIMP_DONE:
                APP_PRINT_INFO0("app_client_callback: discover simp procedure done.");
                break;

            case DISC_SIMP_FAILED:
                APP_PRINT_INFO0("app_client_callback: discover simp request failed.");
                break;

            default:
                break;
            }
            break;

        case SIMP_CLIENT_CB_TYPE_READ_RESULT:
            switch (p_simp_client_cb_data->cb_content.read_result.type)
            {
            case SIMP_READ_V1_READ:
                if (p_simp_client_cb_data->cb_content.read_result.cause == GAP_SUCCESS)
                {
                    value_size = p_simp_client_cb_data->cb_content.read_result.data.v1_read.value_size;
                    p_value = p_simp_client_cb_data->cb_content.read_result.data.v1_read.p_value;
                    APP_PRINT_INFO2("app_client_callback: SIMP_READ_V1_READ value_size %d, value %b",
                                    value_size, TRACE_BINARY(value_size, p_value));
                }
                else
                {
                    APP_PRINT_ERROR1("app_client_callback: SIMP_READ_V1_READ failed cause 0x%x",
                                     p_simp_client_cb_data->cb_content.read_result.cause);
                }
                break;

            case SIMP_READ_V3_NOTIFY_CCCD:
                if (p_simp_client_cb_data->cb_content.read_result.cause == GAP_SUCCESS)
                {
                    APP_PRINT_INFO1("app_client_callback: SIMP_READ_V3_NOTIFY_CCCD notify %d",
                                    p_simp_client_cb_data->cb_content.read_result.data.v3_notify_cccd);
                }
                else
                {
                    APP_PRINT_ERROR1("app_client_callback: SIMP_READ_V3_NOTIFY_CCCD failed cause 0x%x",
                                     p_simp_client_cb_data->cb_content.read_result.cause);
                };
                break;

            case SIMP_READ_V4_INDICATE_CCCD:
                if (p_simp_client_cb_data->cb_content.read_result.cause == GAP_SUCCESS)
                {
                    APP_PRINT_INFO1("app_client_callback: SIMP_READ_V4_INDICATE_CCCD indicate %d",
                                    p_simp_client_cb_data->cb_content.read_result.data.v4_indicate_cccd);
                }
                else
                {
                    APP_PRINT_ERROR1("app_client_callback: SIMP_READ_V4_INDICATE_CCCD failed cause 0x%x",
                                     p_simp_client_cb_data->cb_content.read_result.cause);
                };
                break;

            default:
                break;
            }
            break;

        case SIMP_CLIENT_CB_TYPE_WRITE_RESULT:
            switch (p_simp_client_cb_data->cb_content.write_result.type)
            {
            case SIMP_WRITE_V2_WRITE:
                APP_PRINT_INFO1("app_client_callback: SIMP_WRITE_V2_WRITE write result 0x%x",
                                p_simp_client_cb_data->cb_content.write_result.cause);
                break;

            case SIMP_WRITE_V3_NOTIFY_CCCD:
                APP_PRINT_INFO1("app_client_callback: SIMP_WRITE_V3_NOTIFY_CCCD write result 0x%x",
                                p_simp_client_cb_data->cb_content.write_result.cause);
                break;

            case SIMP_WRITE_V4_INDICATE_CCCD:
                APP_PRINT_INFO1("app_client_callback: SIMP_WRITE_V4_INDICATE_CCCD write result 0x%x",
                                p_simp_client_cb_data->cb_content.write_result.cause);
                break;

            default:
                break;
            }
            break;

        case SIMP_CLIENT_CB_TYPE_NOTIF_IND_RESULT:
            switch (p_simp_client_cb_data->cb_content.notif_ind_data.type)
            {
            case SIMP_V3_NOTIFY:
                value_size = p_simp_client_cb_data->cb_content.notif_ind_data.data.value_size;
                p_value = p_simp_client_cb_data->cb_content.notif_ind_data.data.p_value;
                APP_PRINT_INFO2("app_client_callback: SIMP_V3_NOTIFY value_size %d, value %b",
                                value_size, TRACE_BINARY(value_size, p_value));
                break;

            case SIMP_V4_INDICATE:
                value_size = p_simp_client_cb_data->cb_content.notif_ind_data.data.value_size;
                p_value = p_simp_client_cb_data->cb_content.notif_ind_data.data.p_value;
                APP_PRINT_INFO2("app_client_callback: SIMP_V4_INDICATE value_size %d, value %b",
                                value_size, TRACE_BINARY(value_size, p_value));
                break;

            default:
                break;
            }
            break;

        default:
            break;
        }
    }
    else if (client_id == bas_client_id)
    {
        T_BAS_CLIENT_CB_DATA *p_bas_cb_data = (T_BAS_CLIENT_CB_DATA *)p_data;
        switch (p_bas_cb_data->cb_type)
        {
        case BAS_CLIENT_CB_TYPE_DISC_STATE:
            switch (p_bas_cb_data->cb_content.disc_state)
            {
            case DISC_BAS_DONE:
                APP_PRINT_INFO0("app_client_callback: discover bas procedure done");
                break;

            case DISC_BAS_FAILED:
                APP_PRINT_INFO0("app_client_callback: discover bas procedure failed");
                break;

            default:
                break;
            }
            break;

        case BAS_CLIENT_CB_TYPE_READ_RESULT:
            switch (p_bas_cb_data->cb_content.read_result.type)
            {
            case BAS_READ_BATTERY_LEVEL:
                if (p_bas_cb_data->cb_content.read_result.cause == GAP_SUCCESS)
                {
                    APP_PRINT_INFO1("app_client_callback: BAS_READ_BATTERY_LEVEL battery level %d",
                                    p_bas_cb_data->cb_content.read_result.data.battery_level);
                }
                else
                {
                    APP_PRINT_ERROR1("app_client_callback: BAS_READ_BATTERY_LEVEL failed cause 0x%x",
                                     p_bas_cb_data->cb_content.read_result.cause);
                }
                break;

            case BAS_READ_NOTIFY:
                if (p_bas_cb_data->cb_content.read_result.cause == GAP_SUCCESS)
                {
                    APP_PRINT_INFO1("app_client_callback: BAS_READ_NOTIFY notify %d",
                                    p_bas_cb_data->cb_content.read_result.data.notify);
                }
                else
                {
                    APP_PRINT_ERROR1("app_client_callback: BAS_READ_NOTIFY failed cause 0x%x",
                                     p_bas_cb_data->cb_content.read_result.cause);
                };
                break;

            default:
                break;
            }
            break;

        case BAS_CLIENT_CB_TYPE_WRITE_RESULT:
            switch (p_bas_cb_data->cb_content.write_result.type)
            {
            case BAS_WRITE_NOTIFY_ENABLE:
                APP_PRINT_INFO1("app_client_callback: BAS_WRITE_NOTIFY_ENABLE write result 0x%x",
                                p_bas_cb_data->cb_content.write_result.cause);
                break;

            case BAS_WRITE_NOTIFY_DISABLE:
                APP_PRINT_INFO1("app_client_callback: BAS_WRITE_NOTIFY_DISABLE write result 0x%x",
                                p_bas_cb_data->cb_content.write_result.cause);
                break;

            default:
                break;
            }
            break;

        case BAS_CLIENT_CB_TYPE_NOTIF_IND_RESULT:
            APP_PRINT_INFO1("app_client_callback: BAS_CLIENT_CB_TYPE_NOTIF_IND_RESULT battery level %d",
                            p_bas_cb_data->cb_content.notify_data.battery_level);
            break;

        default:
            break;
        }
    }

    return result;
}
/**
 * @brief app_client_init
          Add GATT clients and register callbacks
 * @return void
 */
void app_client_init(void)
{
    client_init(3);
    gaps_client_id  = gaps_add_client(app_client_callback, APP_MAX_LINKS);
    simple_ble_client_id = simp_ble_add_client(app_client_callback, APP_MAX_LINKS);
    bas_client_id = bas_add_client(app_client_callback, APP_MAX_LINKS);
}
/** @} */ /* End of group CENTRAL_CLIENT_CALLBACK */
/** End of SCATTERNET_APP
* @}
*/
```

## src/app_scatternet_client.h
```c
/*
 * Copyright (c) 2026, Realtek Semiconductor Corporation
 *
 * SPDX-License-Identifier: LicenseRef-Realtek-5-Clause
 */

#ifndef _APP_SCATTERNET_CLIENT__
#define _APP_SCATTERNET_CLIENT__

#ifdef __cplusplus
extern "C" {
#endif

/*============================================================================*
 *                              Header Files
 *============================================================================*/
#include "profile_client.h"

/** @defgroup  SCATTERNET_APP Scatternet Application
    * @brief This file handles BLE Scatternet application routines.
    * @{
    */
/*============================================================================*
 *                              Functions
 *============================================================================*/
extern T_CLIENT_ID simple_ble_client_id;/**< Simple ble service client id*/
extern T_CLIENT_ID gaps_client_id;/**< gap service client id*/
extern T_CLIENT_ID bas_client_id;/**< battery service client id*/

/**
 * @brief app_client_init
          Add GATT clients and register callbacks
 * @return void
 */
void app_client_init(void);

/** End of SCATTERNET_APP
* @}
*/
#ifdef __cplusplus
}
#endif
#endif
```

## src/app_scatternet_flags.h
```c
/*
 * Copyright (c) 2026, Realtek Semiconductor Corporation
 *
 * SPDX-License-Identifier: LicenseRef-Realtek-5-Clause
 */

#ifndef _APP_SCATTERNET_FLAGS_H_
#define _APP_SCATTERNET_FLAGS_H_

/** @defgroup  SCATTERNET_Config Scatternet App Configuration
    * @brief This file is used to config app functions.
    * @{
    */
/*============================================================================*
 *                              Constants
 *============================================================================*/
/** @brief  Config APP LE link number */
#define APP_MAX_LINKS 2

/** @brief  Config airplane mode support: 0-Not built in, 1-built in, use user command to set*/
#define F_BT_AIRPLANE_MODE_SUPPORT 0

/** @brief  Config device name characteristic and appearance characteristic property: 0-Not writeable, 1-writeable, save to flash*/
#define F_BT_GAPS_CHAR_WRITEABLE 0

/** @brief  Config set physical: 0-Not built in, 1-built in, use user command to set*/
#define F_BT_LE_5_0_SET_PHY_SUPPORT 1

/** @brief  Config local address type: 0-pulic address, 1-static random address */
#define F_BT_LE_USE_STATIC_RANDOM_ADDR 0

#define F_APP_GATT_SERVER_EXT_API_SUPPORT 1
/** @} */ /* End of group SCATTERNET_Config */
#endif
```

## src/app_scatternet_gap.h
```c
/*
 * Copyright (c) 2026, Realtek Semiconductor Corporation
 *
 * SPDX-License-Identifier: LicenseRef-Realtek-5-Clause
 */

#ifndef _APP_SCATTERNET_GAP_H_
#define _APP_SCATTERNET_GAP_H_

#ifdef __cplusplus
extern "C" {
#endif
/*============================================================================*
 *                              Header Files
 *============================================================================*/
#include "app_msg.h"
#include <profile_client.h>
#include <profile_server.h>

/** @defgroup SCATTERNET_APP Scatternet Application
  * @brief Scatternet Application
  * @{
  */
/*============================================================================*
 *                              Functions
 *============================================================================*/
/**
 * @brief    All the application messages are pre-handled in this function
 * @note     All the IO MSGs are sent to this function, then the event handling
 *           function shall be called according to the MSG type.
 * @param[in] io_msg  IO message data
 * @return   void
 */
void app_handle_io_msg(T_IO_MSG io_msg);

#if F_BT_AIRPLANE_MODE_SUPPORT
void app_gap_common_callback(uint8_t cb_type, void *p_cb_data);
#endif

#if F_BT_GAPS_CHAR_WRITEABLE
T_APP_RESULT gap_service_callback(T_SERVER_ID service_id, void *p_para);
#endif

/**
  * @brief app_gap_init
  * Initialize peripheral and gap bond manager related parameters
  * @return void
  */
void app_gap_init(void);
/** End of SCATTERNET_APP
* @}
*/
#ifdef __cplusplus
}
#endif
#endif
```

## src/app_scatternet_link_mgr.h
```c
/*
 * Copyright (c) 2026, Realtek Semiconductor Corporation
 *
 * SPDX-License-Identifier: LicenseRef-Realtek-5-Clause
 */

#ifndef _APP_SCATTERNET_LINK_MANAGER_H_
#define _APP_SCATTERNET_LINK_MANAGER_H_
/*============================================================================*
 *                              Header Files
 *============================================================================*/
#include "app_msg.h"
#include "gap_conn_le.h"
#include "profile_client.h"

/** @defgroup SCATTERNET_LINK_MGR Scatternet Link Mgr
  * @brief Scatternet Link Mgr
  * @{
  */
/*============================================================================*
 *                              Constants
 *============================================================================*/
/** @brief  Define device list table size. */
#define APP_MAX_DEVICE_INFO 6

/**
 * @brief  Application Link control block defination.
 */
typedef struct
{
    T_GAP_CONN_STATE       conn_state;/**< Connection state. */
    T_GAP_REMOTE_ADDR_TYPE bd_type;/**< remote BD type*/
    uint8_t                bd_addr[GAP_BD_ADDR_LEN];/**< remote BD */
} T_APP_LINK;

/** @addtogroup  SCATTERNET_SCAN_MGR
    * @{
    */
/**
 * @brief  Device list block defination.
 */
typedef struct
{
    uint8_t bd_addr[GAP_BD_ADDR_LEN];/**< remote BD */
    uint8_t bd_type;/**< remote BD type*/
} T_DEV_INFO;

/** @} */

/** @addtogroup  SCATTERNET_RANDOM
    * @{
    */
#if F_BT_LE_USE_STATIC_RANDOM_ADDR
typedef struct
{
    uint8_t is_exist;
    uint8_t reserved;/**< remote BD type*/
    uint8_t bd_addr[GAP_BD_ADDR_LEN];/**< remote BD */
} T_APP_STATIC_RANDOM_ADDR;
#endif
/** @} */
/*============================================================================*
 *                              Variables
 *============================================================================*/
/** @brief  App link table */
extern T_APP_LINK app_link_table[APP_MAX_LINKS];

/** @brief  Device list table, used to save discovered device informations. */
extern T_DEV_INFO dev_list[APP_MAX_DEVICE_INFO];

/** @brief  The number of device informations saved in dev_list. */
extern uint8_t dev_list_count;

/*============================================================================*
 *                              Functions
 *============================================================================*/
/**
 * @brief   Add device information to device list.
 *
 * @param[in] bd_addr Peer device address.
 * @param[in] bd_type Peer device address type.
 * @retval true Success.
 * @retval false Failed, device list is full.
 */
bool link_mgr_add_device(uint8_t *bd_addr, uint8_t bd_type);

/**
 * @brief Clear device list.
 * @retval None.
 */
void link_mgr_clear_device_list(void);

#if F_BT_LE_USE_STATIC_RANDOM_ADDR
uint32_t app_save_static_random_address(T_APP_STATIC_RANDOM_ADDR *p_addr);
uint32_t app_load_static_random_address(T_APP_STATIC_RANDOM_ADDR *p_addr);
#endif
/** End of SCATTERNET_LINK_MGR
* @}
*/
#endif
```
